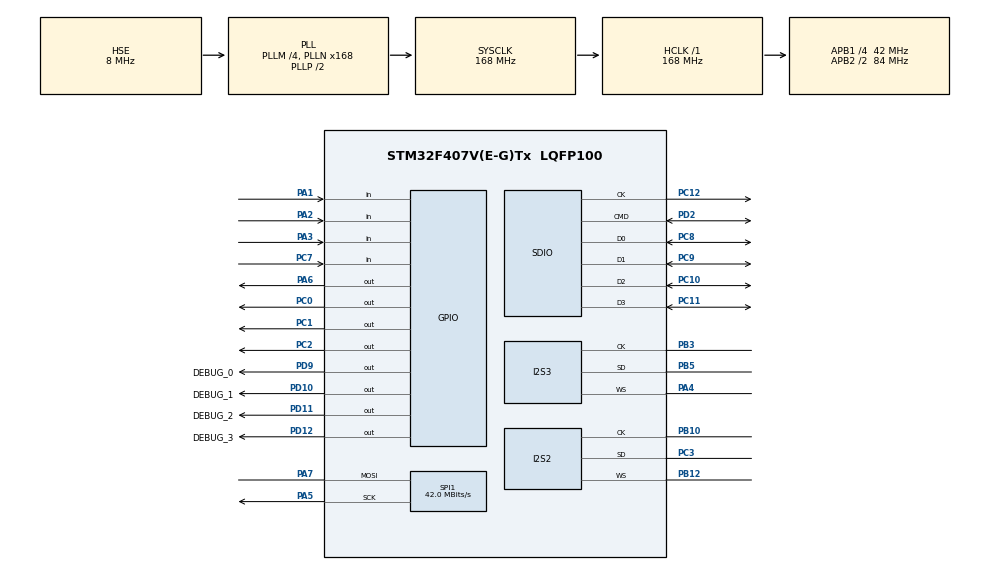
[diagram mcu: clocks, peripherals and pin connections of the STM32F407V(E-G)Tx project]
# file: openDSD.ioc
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Dma.Request0=SPI1_TX
Dma.Request1=SDIO_RX
Dma.Request2=SDIO_TX
Dma.Request3=SPI3_TX
Dma.Request4=SPI2_TX
Dma.SDIO_RX.1.Direction=DMA_PERIPH_TO_MEMORY
Dma.SDIO_RX.1.FIFOMode=DMA_FIFOMODE_ENABLE
Dma.SDIO_RX.1.FIFOThreshold=DMA_FIFO_THRESHOLD_FULL
Dma.SDIO_RX.1.Instance=DMA2_Stream3
Dma.SDIO_RX.1.MemBurst=DMA_MBURST_INC4
Dma.SDIO_RX.1.MemDataAlignment=DMA_MDATAALIGN_WORD
Dma.SDIO_RX.1.MemInc=DMA_MINC_ENABLE
Dma.SDIO_RX.1.Mode=DMA_PFCTRL
Dma.SDIO_RX.1.PeriphBurst=DMA_PBURST_INC4
Dma.SDIO_RX.1.PeriphDataAlignment=DMA_PDATAALIGN_WORD
Dma.SDIO_RX.1.PeriphInc=DMA_PINC_DISABLE
Dma.SDIO_RX.1.Priority=DMA_PRIORITY_LOW
Dma.SDIO_TX.2.Direction=DMA_MEMORY_TO_PERIPH
Dma.SDIO_TX.2.FIFOMode=DMA_FIFOMODE_ENABLE
Dma.SDIO_TX.2.FIFOThreshold=DMA_FIFO_THRESHOLD_FULL
Dma.SDIO_TX.2.Instance=DMA2_Stream6
Dma.SDIO_TX.2.MemBurst=DMA_MBURST_INC4
Dma.SDIO_TX.2.MemDataAlignment=DMA_MDATAALIGN_WORD
Dma.SDIO_TX.2.MemInc=DMA_MINC_ENABLE
Dma.SDIO_TX.2.Mode=DMA_PFCTRL
Dma.SDIO_TX.2.PeriphBurst=DMA_PBURST_INC4
Dma.SDIO_TX.2.PeriphDataAlignment=DMA_PDATAALIGN_WORD
Dma.SDIO_TX.2.PeriphInc=DMA_PINC_DISABLE
Dma.SDIO_TX.2.Priority=DMA_PRIORITY_LOW
Dma.SPI1_TX.0.Direction=DMA_MEMORY_TO_PERIPH
Dma.SPI1_TX.0.FIFOMode=DMA_FIFOMODE_DISABLE
Dma.SPI1_TX.0.Instance=DMA2_Stream5
Dma.SPI1_TX.0.MemDataAlignment=DMA_MDATAALIGN_BYTE
Dma.SPI1_TX.0.MemInc=DMA_MINC_ENABLE
Dma.SPI1_TX.0.Mode=DMA_NORMAL
Dma.SPI1_TX.0.PeriphDataAlignment=DMA_PDATAALIGN_BYTE
Dma.SPI1_TX.0.PeriphInc=DMA_PINC_DISABLE
Dma.SPI1_TX.0.Priority=DMA_PRIORITY_LOW
Dma.SPI2_TX.4.Direction=DMA_MEMORY_TO_PERIPH
Dma.SPI2_TX.4.FIFOMode=DMA_FIFOMODE_DISABLE
Dma.SPI2_TX.4.Instance=DMA1_Stream4
Dma.SPI2_TX.4.MemDataAlignment=DMA_MDATAALIGN_HALFWORD
Dma.SPI2_TX.4.MemInc=DMA_MINC_ENABLE
Dma.SPI2_TX.4.Mode=DMA_CIRCULAR
Dma.SPI2_TX.4.PeriphDataAlignment=DMA_PDATAALIGN_HALFWORD
Dma.SPI2_TX.4.PeriphInc=DMA_PINC_DISABLE
Dma.SPI2_TX.4.Priority=DMA_PRIORITY_MEDIUM
Dma.SPI3_TX.3.Direction=DMA_MEMORY_TO_PERIPH
Dma.SPI3_TX.3.FIFOMode=DMA_FIFOMODE_DISABLE
Dma.SPI3_TX.3.Instance=DMA1_Stream7
Dma.SPI3_TX.3.MemDataAlignment=DMA_MDATAALIGN_HALFWORD
Dma.SPI3_TX.3.MemInc=DMA_MINC_ENABLE
Dma.SPI3_TX.3.Mode=DMA_CIRCULAR
Dma.SPI3_TX.3.PeriphDataAlignment=DMA_PDATAALIGN_HALFWORD
Dma.SPI3_TX.3.PeriphInc=DMA_PINC_DISABLE
Dma.SPI3_TX.3.Priority=DMA_PRIORITY_MEDIUM
FATFS.BSP.number=1
FATFS.USE_DMA_CODE_SD=1
FATFS._MAX_SS=4096
FATFS._MIN_SS=512
FATFS._USE_FIND=1
FATFS._USE_LFN=2
FATFS0.BSP.STBoard=false
FATFS0.BSP.api=Unknown
FATFS0.BSP.i2caddr=0
FATFS0.BSP.instance=PC7
FATFS0.BSP.ip=GPIO
FATFS0.BSP.mode=Input
FATFS0.BSP.name=Detect_SDIO
FATFS0.BSP.solution=PC7
I2S2.AudioFreq=AudioFreqCustomValue
I2S2.AudioFreqCustom=88200
I2S2.DataFormat=I2S_DATAFORMAT_16B
I2S2.ErrorAudioFreq=-0.12 %
I2S2.FullDuplexMode=I2S_FULLDUPLEXMODE_DISABLE
I2S2.Instance=SPI$Index
I2S2.RealAudioFreq=87.89 KHz
I2S2.Standard=I2S_STANDARD_MSB
I2S2.VirtualMode=I2S_MODE_MASTER
I2S3.AudioFreq=AudioFreqCustomValue
I2S3.AudioFreqCustom=88200
I2S3.DataFormat=I2S_DATAFORMAT_16B
I2S3.ErrorAudioFreq=-0.12 %
I2S3.FullDuplexMode=I2S_FULLDUPLEXMODE_DISABLE
I2S3.Instance=SPI$Index
I2S3.RealAudioFreq=87.89 KHz
I2S3.Standard=I2S_STANDARD_MSB
I2S3.VirtualMode=I2S_MODE_MASTER
Mcu.Family=STM32F4
Mcu.Name=STM32F407V(E-G)Tx
Mcu.Package=LQFP100
NVIC.DMA1_Stream4_IRQn=true\:0\:0\:false\:false\:true\:false\:true
NVIC.DMA1_Stream7_IRQn=true\:0\:0\:false\:false\:true\:false\:true
NVIC.DMA2_Stream3_IRQn=true\:0\:0\:false\:false\:true\:false\:true
NVIC.DMA2_Stream5_IRQn=true\:0\:0\:false\:false\:true\:false\:true
NVIC.DMA2_Stream6_IRQn=true\:0\:0\:false\:false\:true\:false\:true
NVIC.PriorityGroup=NVIC_PRIORITYGROUP_4
NVIC.SDIO_IRQn=true\:0\:0\:false\:false\:true\:true\:true
NVIC.SPI3_IRQn=true\:0\:0\:false\:false\:true\:true\:true
PA1.GPIO_Mode=GPIO_MODE_INPUT
PA1.GPIO_PuPd=GPIO_NOPULL
PA1.Signal=GPIO_Input
PA13.Mode=Serial_Wire
PA13.Signal=SYS_JTMS-SWDIO
PA14.Mode=Serial_Wire
PA14.Signal=SYS_JTCK-SWCLK
PA2.GPIO_Mode=GPIO_MODE_INPUT
PA2.GPIO_PuPd=GPIO_NOPULL
PA2.Signal=GPIO_Input
PA3.GPIO_Mode=GPIO_MODE_INPUT
PA3.GPIO_PuPd=GPIO_NOPULL
PA3.Signal=GPIO_Input
PA4.GPIO_Mode=GPIO_MODE_AF_PP
PA4.GPIO_PuPd=GPIO_NOPULL
PA4.GPIO_Speed=GPIO_SPEED_FREQ_VERY_HIGH
PA4.Mode=Half_Duplex_Master
PA4.Signal=I2S3_WS
PA5.GPIO_Mode=GPIO_MODE_AF_PP
PA5.GPIO_PuPd=GPIO_NOPULL
PA5.GPIO_Speed=GPIO_SPEED_FREQ_VERY_HIGH
PA5.Mode=Simplex_Bidirectional_Master
PA5.Signal=SPI1_SCK
PA6.GPIO_ModeDefaultOutputPP=GPIO_MODE_OUTPUT_PP
PA6.GPIO_PuPd=GPIO_NOPULL
PA6.GPIO_Speed=GPIO_SPEED_FREQ_LOW
PA6.PinState=GPIO_PIN_RESET
PA6.Signal=GPIO_Output
PA7.GPIO_Mode=GPIO_MODE_AF_PP
PA7.GPIO_PuPd=GPIO_NOPULL
PA7.GPIO_Speed=GPIO_SPEED_FREQ_VERY_HIGH
PA7.Mode=Simplex_Bidirectional_Master
PA7.Signal=SPI1_MOSI
PB10.GPIO_Mode=GPIO_MODE_AF_PP
PB10.GPIO_PuPd=GPIO_NOPULL
PB10.GPIO_Speed=GPIO_SPEED_FREQ_VERY_HIGH
PB10.Mode=Half_Duplex_Master
PB10.Signal=I2S2_CK
PB12.GPIO_Mode=GPIO_MODE_AF_PP
PB12.GPIO_PuPd=GPIO_NOPULL
PB12.GPIO_Speed=GPIO_SPEED_FREQ_VERY_HIGH
PB12.Mode=Half_Duplex_Master
PB12.Signal=I2S2_WS
PB3.GPIO_Mode=GPIO_MODE_AF_PP
PB3.GPIO_PuPd=GPIO_NOPULL
PB3.GPIO_Speed=GPIO_SPEED_FREQ_VERY_HIGH
PB3.Mode=Half_Duplex_Master
PB3.Signal=I2S3_CK
PB5.GPIO_Mode=GPIO_MODE_AF_PP
PB5.GPIO_PuPd=GPIO_NOPULL
PB5.GPIO_Speed=GPIO_SPEED_FREQ_VERY_HIGH
PB5.Mode=Half_Duplex_Master
PB5.Signal=I2S3_SD
PC0.GPIO_ModeDefaultOutputPP=GPIO_MODE_OUTPUT_PP
PC0.GPIO_PuPd=GPIO_NOPULL
PC0.GPIO_Speed=GPIO_SPEED_FREQ_LOW
PC0.PinState=GPIO_PIN_RESET
PC0.Signal=GPIO_Output
PC1.GPIO_ModeDefaultOutputPP=GPIO_MODE_OUTPUT_PP
PC1.GPIO_PuPd=GPIO_NOPULL
PC1.GPIO_Speed=GPIO_SPEED_FREQ_LOW
PC1.PinState=GPIO_PIN_RESET
PC1.Signal=GPIO_Output
PC10.Mode=SD_4_bits_Wide_bus
PC10.Signal=SDIO_D2
PC11.Mode=SD_4_bits_Wide_bus
PC11.Signal=SDIO_D3
PC12.Mode=SD_4_bits_Wide_bus
PC12.Signal=SDIO_CK
PC14-OSC32_IN.Mode=LSE-External-Oscillator
PC14-OSC32_IN.Signal=RCC_OSC32_IN
PC15-OSC32_OUT.Mode=LSE-External-Oscillator
PC15-OSC32_OUT.Signal=RCC_OSC32_OUT
PC2.GPIO_ModeDefaultOutputPP=GPIO_MODE_OUTPUT_PP
PC2.GPIO_PuPd=GPIO_NOPULL
PC2.GPIO_Speed=GPIO_SPEED_FREQ_LOW
PC2.PinState=GPIO_PIN_RESET
PC2.Signal=GPIO_Output
PC3.GPIO_Mode=GPIO_MODE_AF_PP
PC3.GPIO_PuPd=GPIO_NOPULL
PC3.GPIO_Speed=GPIO_SPEED_FREQ_VERY_HIGH
PC3.Mode=Half_Duplex_Master
PC3.Signal=I2S2_SD
PC7.GPIO_Mode=GPIO_MODE_INPUT
PC7.GPIO_PuPd=GPIO_NOPULL
PC7.Signal=GPIO_Input
PC8.Mode=SD_4_bits_Wide_bus
PC8.Signal=SDIO_D0
PC9.Mode=SD_4_bits_Wide_bus
PC9.Signal=SDIO_D1
PD10.GPIO_Label=DEBUG_1
PD10.GPIO_ModeDefaultOutputPP=GPIO_MODE_OUTPUT_PP
PD10.GPIO_PuPd=GPIO_NOPULL
PD10.GPIO_Speed=GPIO_SPEED_FREQ_LOW
PD10.PinState=GPIO_PIN_RESET
PD10.Signal=GPIO_Output
PD11.GPIO_Label=DEBUG_2
PD11.GPIO_ModeDefaultOutputPP=GPIO_MODE_OUTPUT_PP
PD11.GPIO_PuPd=GPIO_NOPULL
PD11.GPIO_Speed=GPIO_SPEED_FREQ_LOW
PD11.PinState=GPIO_PIN_RESET
PD11.Signal=GPIO_Output
PD12.GPIO_Label=DEBUG_3
PD12.GPIO_ModeDefaultOutputPP=GPIO_MODE_OUTPUT_PP
PD12.GPIO_PuPd=GPIO_NOPULL
PD12.GPIO_Speed=GPIO_SPEED_FREQ_LOW
PD12.PinState=GPIO_PIN_RESET
PD12.Signal=GPIO_Output
PD2.Mode=SD_4_bits_Wide_bus
PD2.Signal=SDIO_CMD
PD9.GPIO_Label=DEBUG_0
PD9.GPIO_ModeDefaultOutputPP=GPIO_MODE_OUTPUT_PP
PD9.GPIO_PuPd=GPIO_NOPULL
PD9.GPIO_Speed=GPIO_SPEED_FREQ_LOW
PD9.PinState=GPIO_PIN_RESET
PD9.Signal=GPIO_Output
PH0-OSC_IN.Mode=HSE-External-Oscillator
PH0-OSC_IN.Signal=RCC_OSC_IN
PH1-OSC_OUT.Mode=HSE-External-Oscillator
PH1-OSC_OUT.Signal=RCC_OSC_OUT
ProjectManager.HeapSize=0x4000
ProjectManager.StackSize=0x800
ProjectManager.TargetToolchain=STM32CubeIDE
RCC.48MHZClocksFreq_Value=48000000
RCC.AHBFreq_Value=168000000
RCC.APB1CLKDivider=RCC_HCLK_DIV4
RCC.APB1Freq_Value=42000000
RCC.APB1TimFreq_Value=84000000
RCC.APB2CLKDivider=RCC_HCLK_DIV2
RCC.APB2Freq_Value=84000000
RCC.APB2TimFreq_Value=168000000
RCC.CortexFreq_Value=168000000
RCC.HCLKFreq_Value=168000000
RCC.HSE_VALUE=8000000
RCC.HSI_VALUE=16000000
RCC.PLLI2SN=180
RCC.PLLM=4
RCC.PLLN=168
RCC.PLLQ=7
RCC.PLLSourceVirtual=RCC_PLLSOURCE_HSE
RCC.RCC_RTC_Clock_Source=RCC_RTCCLKSOURCE_LSE
RCC.RCC_RTC_Clock_SourceVirtual=RCC_RTCCLKSOURCE_LSE
RCC.SYSCLKFreq_VALUE=168000000
RCC.SYSCLKSource=RCC_SYSCLKSOURCE_PLLCLK
RCC.VCOOutputFreq_Value=336000000
SDIO.ClockDiv=3
SDIO.HardwareFlowControl=SDIO_HARDWARE_FLOW_CONTROL_ENABLE
SPI1.BaudRatePrescaler=SPI_BAUDRATEPRESCALER_2
SPI1.CalculateBaudRate=42.0 MBits/s
SPI1.Direction=SPI_DIRECTION_1LINE
SPI1.Mode=SPI_MODE_MASTER
SPI1.VirtualType=VM_MASTER
VP_FATFS_VS_SDIO.Mode=SDIO
VP_RTC_VS_RTC_Activate.Mode=RTC_Enabled
board=custom

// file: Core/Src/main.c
/* USER CODE BEGIN Header */
/**
  ******************************************************************************
  * @file           : main.c
  * @brief          : Main program body
  ******************************************************************************
  * @attention
  *
  * <h2><center>&copy; Copyright (c) 2020 STMicroelectronics.
  * All rights reserved.</center></h2>
  *
  * This software component is licensed by ST under Ultimate Liberty license
  * SLA0044, the "License"; You may not use this file except in compliance with
  * the License. You may obtain a copy of the License at:
  *                             www.st.com/SLA0044
  *
  ******************************************************************************
  */
/* USER CODE END Header */

#include "main.h"
#include "fatfs.h"

I2S_HandleTypeDef hi2s2;
I2S_HandleTypeDef hi2s3;
DMA_HandleTypeDef hdma_spi2_tx;
DMA_HandleTypeDef hdma_spi3_tx;

RTC_HandleTypeDef hrtc;

SD_HandleTypeDef hsd;
DMA_HandleTypeDef hdma_sdio_rx;
DMA_HandleTypeDef hdma_sdio_tx;

SPI_HandleTypeDef hspi1;
DMA_HandleTypeDef hdma_spi1_tx;

void SystemClock_Config(void);
static void MX_GPIO_Init(void);
static void MX_DMA_Init(void);
static void MX_RTC_Init(void);
static void MX_SDIO_SD_Init(void);
static void MX_I2S2_Init(void);
static void MX_I2S3_Init(void);
static void MX_SPI1_Init(void);

int main(void)
{

  /* MCU Configuration--------------------------------------------------------*/

  /* Reset of all peripherals, Initializes the Flash interface and the Systick. */
  HAL_Init();

  /* Configure the system clock */
  SystemClock_Config();

  /* Initialize all configured peripherals */
  MX_GPIO_Init();
  MX_DMA_Init();
  MX_RTC_Init();
  MX_SDIO_SD_Init();
  MX_FATFS_Init();
  MX_I2S2_Init();
  MX_I2S3_Init();
  MX_SPI1_Init();
  /* USER CODE BEGIN 2 */
  easy_dsd_start_task();
  /* USER CODE END 2 */

  /* Infinite loop */
  while (1)
  {

  }
}

void SystemClock_Config(void)
{
  RCC_OscInitTypeDef RCC_OscInitStruct = {0};
  RCC_ClkInitTypeDef RCC_ClkInitStruct = {0};
  RCC_PeriphCLKInitTypeDef PeriphClkInitStruct = {0};

  /** Configure the main internal regulator output voltage
  */
  __HAL_RCC_PWR_CLK_ENABLE();
  __HAL_PWR_VOLTAGESCALING_CONFIG(PWR_REGULATOR_VOLTAGE_SCALE1);
  /** Initializes the CPU, AHB and APB busses clocks
  */
  RCC_OscInitStruct.OscillatorType = RCC_OSCILLATORTYPE_HSE|RCC_OSCILLATORTYPE_LSE;
  RCC_OscInitStruct.HSEState = RCC_HSE_ON;
  RCC_OscInitStruct.LSEState = RCC_LSE_ON;
  RCC_OscInitStruct.PLL.PLLState = RCC_PLL_ON;
  RCC_OscInitStruct.PLL.PLLSource = RCC_PLLSOURCE_HSE;
  RCC_OscInitStruct.PLL.PLLM = 4;
  RCC_OscInitStruct.PLL.PLLN = 168;
  RCC_OscInitStruct.PLL.PLLP = RCC_PLLP_DIV2;
  RCC_OscInitStruct.PLL.PLLQ = 7;
  if (HAL_RCC_OscConfig(&RCC_OscInitStruct) != HAL_OK)
  {
    Error_Handler();
  }
  /** Initializes the CPU, AHB and APB busses clocks
  */
  RCC_ClkInitStruct.ClockType = RCC_CLOCKTYPE_HCLK|RCC_CLOCKTYPE_SYSCLK
                              |RCC_CLOCKTYPE_PCLK1|RCC_CLOCKTYPE_PCLK2;
  RCC_ClkInitStruct.SYSCLKSource = RCC_SYSCLKSOURCE_PLLCLK;
  RCC_ClkInitStruct.AHBCLKDivider = RCC_SYSCLK_DIV1;
  RCC_ClkInitStruct.APB1CLKDivider = RCC_HCLK_DIV4;
  RCC_ClkInitStruct.APB2CLKDivider = RCC_HCLK_DIV2;

  if (HAL_RCC_ClockConfig(&RCC_ClkInitStruct, FLASH_LATENCY_5) != HAL_OK)
  {
    Error_Handler();
  }
  PeriphClkInitStruct.PeriphClockSelection = RCC_PERIPHCLK_I2S|RCC_PERIPHCLK_RTC;
  PeriphClkInitStruct.PLLI2S.PLLI2SN = 180;
  PeriphClkInitStruct.PLLI2S.PLLI2SR = 2;
  PeriphClkInitStruct.RTCClockSelection = RCC_RTCCLKSOURCE_LSE;
  if (HAL_RCCEx_PeriphCLKConfig(&PeriphClkInitStruct) != HAL_OK)
  {
    Error_Handler();
  }
}

static void MX_I2S2_Init(void)
{

  hi2s2.Instance = SPI2;
  hi2s2.Init.Mode = I2S_MODE_MASTER_TX;
  hi2s2.Init.Standard = I2S_STANDARD_MSB;
  hi2s2.Init.DataFormat = I2S_DATAFORMAT_16B;
  hi2s2.Init.MCLKOutput = I2S_MCLKOUTPUT_DISABLE;
  hi2s2.Init.AudioFreq = 88200;
  hi2s2.Init.CPOL = I2S_CPOL_LOW;
  hi2s2.Init.ClockSource = I2S_CLOCK_PLL;
  hi2s2.Init.FullDuplexMode = I2S_FULLDUPLEXMODE_DISABLE;
  if (HAL_I2S_Init(&hi2s2) != HAL_OK)
  {
    Error_Handler();
  }

}

static void MX_I2S3_Init(void)
{

  hi2s3.Instance = SPI3;
  hi2s3.Init.Mode = I2S_MODE_MASTER_TX;
  hi2s3.Init.Standard = I2S_STANDARD_MSB;
  hi2s3.Init.DataFormat = I2S_DATAFORMAT_16B;
  hi2s3.Init.MCLKOutput = I2S_MCLKOUTPUT_DISABLE;
  hi2s3.Init.AudioFreq = 88200;
  hi2s3.Init.CPOL = I2S_CPOL_LOW;
  hi2s3.Init.ClockSource = I2S_CLOCK_PLL;
  hi2s3.Init.FullDuplexMode = I2S_FULLDUPLEXMODE_DISABLE;
  if (HAL_I2S_Init(&hi2s3) != HAL_OK)
  {
    Error_Handler();
  }

}

static void MX_RTC_Init(void)
{

  /** Initialize RTC Only
  */
  hrtc.Instance = RTC;
  hrtc.Init.HourFormat = RTC_HOURFORMAT_24;
  hrtc.Init.AsynchPrediv = 127;
  hrtc.Init.SynchPrediv = 255;
  hrtc.Init.OutPut = RTC_OUTPUT_DISABLE;
  hrtc.Init.OutPutPolarity = RTC_OUTPUT_POLARITY_HIGH;
  hrtc.Init.OutPutType = RTC_OUTPUT_TYPE_OPENDRAIN;
  if (HAL_RTC_Init(&hrtc) != HAL_OK)
  {
    Error_Handler();
  }

}

static void MX_SDIO_SD_Init(void)
{

  hsd.Instance = SDIO;
  hsd.Init.ClockEdge = SDIO_CLOCK_EDGE_RISING;
  hsd.Init.ClockBypass = SDIO_CLOCK_BYPASS_DISABLE;
  hsd.Init.ClockPowerSave = SDIO_CLOCK_POWER_SAVE_DISABLE;
  hsd.Init.BusWide = SDIO_BUS_WIDE_1B;
  hsd.Init.HardwareFlowControl = SDIO_HARDWARE_FLOW_CONTROL_ENABLE;
  hsd.Init.ClockDiv = 3;

}

static void MX_SPI1_Init(void)
{

  /* SPI1 parameter configuration*/
  hspi1.Instance = SPI1;
  hspi1.Init.Mode = SPI_MODE_MASTER;
  hspi1.Init.Direction = SPI_DIRECTION_1LINE;
  hspi1.Init.DataSize = SPI_DATASIZE_8BIT;
  hspi1.Init.CLKPolarity = SPI_POLARITY_LOW;
  hspi1.Init.CLKPhase = SPI_PHASE_1EDGE;
  hspi1.Init.NSS = SPI_NSS_SOFT;
  hspi1.Init.BaudRatePrescaler = SPI_BAUDRATEPRESCALER_2;
  hspi1.Init.FirstBit = SPI_FIRSTBIT_MSB;
  hspi1.Init.TIMode = SPI_TIMODE_DISABLE;
  hspi1.Init.CRCCalculation = SPI_CRCCALCULATION_DISABLE;
  hspi1.Init.CRCPolynomial = 10;
  if (HAL_SPI_Init(&hspi1) != HAL_OK)
  {
    Error_Handler();
  }

}

static void MX_DMA_Init(void)
{

  /* DMA controller clock enable */
  __HAL_RCC_DMA2_CLK_ENABLE();
  __HAL_RCC_DMA1_CLK_ENABLE();

  /* DMA interrupt init */
  /* DMA1_Stream4_IRQn interrupt configuration */
  HAL_NVIC_SetPriority(DMA1_Stream4_IRQn, 0, 0);
  HAL_NVIC_EnableIRQ(DMA1_Stream4_IRQn);
  /* DMA1_Stream7_IRQn interrupt configuration */
  HAL_NVIC_SetPriority(DMA1_Stream7_IRQn, 0, 0);
  HAL_NVIC_EnableIRQ(DMA1_Stream7_IRQn);
  /* DMA2_Stream3_IRQn interrupt configuration */
  HAL_NVIC_SetPriority(DMA2_Stream3_IRQn, 0, 0);
  HAL_NVIC_EnableIRQ(DMA2_Stream3_IRQn);
  /* DMA2_Stream5_IRQn interrupt configuration */
  HAL_NVIC_SetPriority(DMA2_Stream5_IRQn, 0, 0);
  HAL_NVIC_EnableIRQ(DMA2_Stream5_IRQn);
  /* DMA2_Stream6_IRQn interrupt configuration */
  HAL_NVIC_SetPriority(DMA2_Stream6_IRQn, 0, 0);
  HAL_NVIC_EnableIRQ(DMA2_Stream6_IRQn);

}

static void MX_GPIO_Init(void)
{
  GPIO_InitTypeDef GPIO_InitStruct = {0};

  /* GPIO Ports Clock Enable */
  __HAL_RCC_GPIOC_CLK_ENABLE();
  __HAL_RCC_GPIOH_CLK_ENABLE();
  __HAL_RCC_GPIOA_CLK_ENABLE();
  __HAL_RCC_GPIOB_CLK_ENABLE();
  __HAL_RCC_GPIOD_CLK_ENABLE();

  /*Configure GPIO pin Output Level */
  HAL_GPIO_WritePin(GPIOC, GPIO_PIN_0|GPIO_PIN_1|GPIO_PIN_2, GPIO_PIN_RESET);

  /*Configure GPIO pin Output Level */
  HAL_GPIO_WritePin(GPIOA, GPIO_PIN_6, GPIO_PIN_RESET);

  /*Configure GPIO pin Output Level */
  HAL_GPIO_WritePin(GPIOD, DEBUG_0_Pin|DEBUG_1_Pin|DEBUG_2_Pin|DEBUG_3_Pin, GPIO_PIN_RESET);

  /*Configure GPIO pins : PC0 PC1 PC2 */
  GPIO_InitStruct.Pin = GPIO_PIN_0|GPIO_PIN_1|GPIO_PIN_2;
  GPIO_InitStruct.Mode = GPIO_MODE_OUTPUT_PP;
  GPIO_InitStruct.Pull = GPIO_NOPULL;
  GPIO_InitStruct.Speed = GPIO_SPEED_FREQ_LOW;
  HAL_GPIO_Init(GPIOC, &GPIO_InitStruct);

  /*Configure GPIO pins : PA1 PA2 PA3 */
  GPIO_InitStruct.Pin = GPIO_PIN_1|GPIO_PIN_2|GPIO_PIN_3;
  GPIO_InitStruct.Mode = GPIO_MODE_INPUT;
  GPIO_InitStruct.Pull = GPIO_NOPULL;
  HAL_GPIO_Init(GPIOA, &GPIO_InitStruct);

  /*Configure GPIO pin : PA6 */
  GPIO_InitStruct.Pin = GPIO_PIN_6;
  GPIO_InitStruct.Mode = GPIO_MODE_OUTPUT_PP;
  GPIO_InitStruct.Pull = GPIO_NOPULL;
  GPIO_InitStruct.Speed = GPIO_SPEED_FREQ_LOW;
  HAL_GPIO_Init(GPIOA, &GPIO_InitStruct);

  /*Configure GPIO pins : DEBUG_0_Pin DEBUG_1_Pin DEBUG_2_Pin DEBUG_3_Pin */
  GPIO_InitStruct.Pin = DEBUG_0_Pin|DEBUG_1_Pin|DEBUG_2_Pin|DEBUG_3_Pin;
  GPIO_InitStruct.Mode = GPIO_MODE_OUTPUT_PP;
  GPIO_InitStruct.Pull = GPIO_NOPULL;
  GPIO_InitStruct.Speed = GPIO_SPEED_FREQ_LOW;
  HAL_GPIO_Init(GPIOD, &GPIO_InitStruct);

  /*Configure GPIO pin : PC7 */
  GPIO_InitStruct.Pin = GPIO_PIN_7;
  GPIO_InitStruct.Mode = GPIO_MODE_INPUT;
  GPIO_InitStruct.Pull = GPIO_NOPULL;
  HAL_GPIO_Init(GPIOC, &GPIO_InitStruct);

}

void Error_Handler(void)
{
}

/************************ (C) COPYRIGHT STMicroelectronics *****END OF FILE****/
